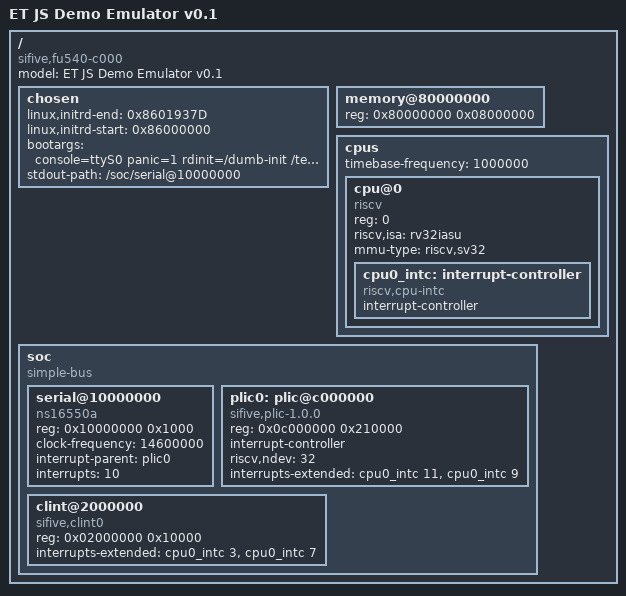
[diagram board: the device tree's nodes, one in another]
/dts-v1/;

/ {
	#address-cells = <1>;
	#size-cells = <1>;
	//compatible = "riscv-virtio";
	compatible = "sifive,fu540-c000";
	model = "ET JS Demo Emulator v0.1";

	chosen {
		linux,initrd-end = <0x8601937D>;
		linux,initrd-start = <0x86000000>;
		bootargs = "console=ttyS0 panic=1 rdinit=/dumb-init /testprogram";
		stdout-path = "/soc/serial@10000000";
	};

	memory@80000000 {
		device_type = "memory";
		reg = <0x80000000 0x08000000>;
	};

	cpus {
		#address-cells = <1>;
		#size-cells = <0>;
		timebase-frequency = <1000000>;

		cpu@0 {
			device_type = "cpu";
			compatible = "riscv";
			reg = <0>;
			status = "okay";
			riscv,isa = "rv32iasu";
			mmu-type = "riscv,sv32";

			cpu0_intc: interrupt-controller {
				#interrupt-cells = <1>;
				compatible = "riscv,cpu-intc";
				interrupt-controller;
			};
		};

	};

	/*
	fxd_clock: clock {
		#clock-cells = <0>;
		compatible = "fixed-clock";
		clock-frequency = <1000000>;
	};
	*/

	soc {
		#address-cells = <1>;
		#size-cells = <1>;
		compatible = "simple-bus";
		ranges;

		serial@10000000 {
			compatible = "ns16550a";
			//compatible = "sifive,fu540-c000-uart", "sifive,uart0";
			reg = <0x10000000 0x1000>;
			//reg = <0x10011000 0x1000>;
			clock-frequency = <14600000>;
			//clocks = <&fxd_clock>;
			interrupt-parent = <&plic0>;
			interrupts = <10>;
			//interrupts = <1>;
		};

		//plic0: plic@40000000 {
		plic0: plic@c000000 {
			#address-cells = <0>;
			#interrupt-cells = <1>;
			compatible = "sifive,plic-1.0.0", "riscv,plic0";
			//reg = <0x40000000 0x210000>;
			reg = <0x0c000000 0x210000>;
			interrupt-controller;
			riscv,ndev = <32>;
			interrupts-extended = <
				&cpu0_intc 11 &cpu0_intc 9
			>;
		};

		//clint@32000000 {
		clint@2000000 {
			compatible = "sifive,clint0", "riscv,clint0";
			//reg = <0x32000000 0x10000>;
			reg = <0x02000000 0x10000>;
			interrupts-extended = <
				&cpu0_intc 3 &cpu0_intc 7
			>;
		};
	};
};

// Build With:
// dtc -I dts -O dtb -o ./echelon_emu_v0.1.1.dtb ./echelon_emu_v0.1.1.dts
